# IMC300A register map
Vendor: Infineon; File version: 1.0.0
CPU: CM0 r0p0, little endian, no MPU, no FPU, 2 interrupt priority bits
Registers are 32-bit, read-write, reset 0x0 unless marked. A register's access mark holds for its fields unless they carry their own. Offsets are from the block's base; [hi:lo] are bit positions; {n}, {i} and the like mark numbered series; 'fields as' and 'values as' point back to an identical list.

## PORT1
Base 0x40040100
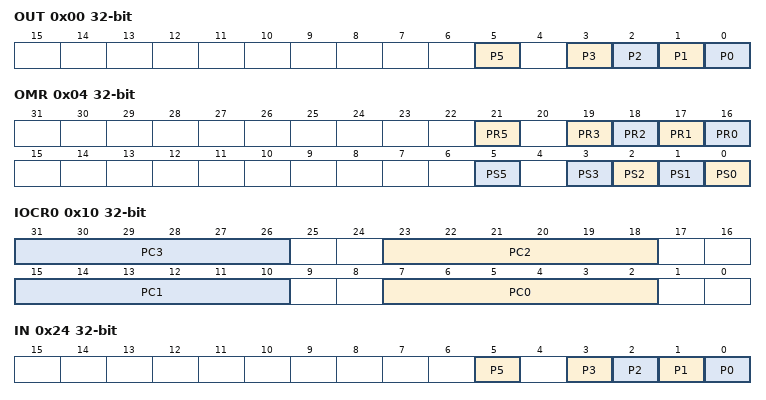
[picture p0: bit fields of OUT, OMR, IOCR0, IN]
0x00 OUT — Port 1 Output Register
  [all] fields
    0=The output level of P1.x is 0; 1=The output level of P1.x is 1
  [5] P5 — Port 1 Output Bit 5
  [n] P{n} (n=0..3) — Port 1 Output Bit {n}
0x04 OMR wo — Port 1 Output Modification Register
  [21] PR5 — Port 1 Reset Bit 5
  [n+16] PR{n} (n=0..3) — Port 1 Reset Bit {n}
  [5] PS5 — Port 1 Set Bit 5
  [n] PS{n} (n=0..3) — Port 1 Set Bit {n}
0x10 IOCR0 — Port 1 Input/Output Control Register 0
  [all] fields
    0=Input - No internal pull device active; 1=Input - Internal pull-down device active; 2=Input - Internal pull-up device active; 3=Input - No internal pull device, Pn_OUTx = input value; 4=Input inverted - No internal pull device active; 5=Input inverted - Internal pull-down device active; 6=Input inverted - Internal pull-up device active; 7=Input inverted - No internal pull device, Pn_OUTx = input value; 32=Output Push-Pull - General-purpose output; {v}=Output Push-Pull - Alternate output function {v-32} (v=33..41); 48=Output Open Drain - General-purpose output; {v}=Output Open Drain - Alternate output function {v-48} (v=49..57)
  [8n+7:8n+2] PC{n} (n=0..3) — Port Control for Port 1 Pin {n}
0x14 IOCR4 — Port 1 Input/Output Control Register 4
  [15:10] PC5 — Port Control for Port 1 Pin 5
    values as the fields of IOCR0
0x24 IN ro (reset mask 0xFFFFF000) — Port 1 Input Register
  [all] fields
    0=The input level of P1.x is 0; 1=The input level of P1.x is 1
  [5] P5 — Port 1 Input Bit 5
  [n] P{n} (n=0..3) — Port 1 Input Bit {n}
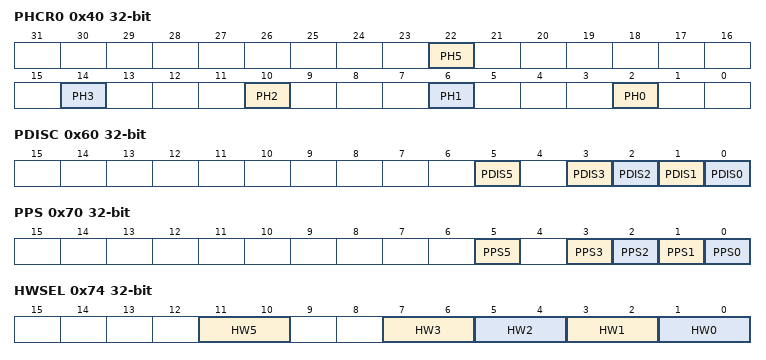
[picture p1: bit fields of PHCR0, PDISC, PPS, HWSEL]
0x40 PHCR0 — Port 1 Pad Hysteresis Control Register 0
  [22] PH5 — Pad Hysteresis for P1.5
  [14] PH3 — Pad Hysteresis for P1.3
  [10] PH2 — Pad Hysteresis for P1.2
  [6] PH1 — Pad Hysteresis for P1.1
  [2] PH0 — Pad Hysteresis for P1.0
0x60 PDISC ro (reset mask 0xFFFFF000) — Port 1 Pin Function Decision Control Register
  [all] fields
    0=Pad P1.x is enabled; 1=Pad P1.x is disabled
  [5] PDIS5 — Pad Disable for Port 1 Pin 5
  [n] PDIS{n} (n=0..3) — Pad Disable for Port 1 Pin {n}
0x70 PPS — Port 1 Pin Power Save Register
  [all] fields
    0=Pin Power Save of P1.x is disabled; 1=Pin Power Save of P1.x is enabled
  [5] PPS5 — Port 1 Pin Power Save Bit 5
  [n] PPS{n} (n=0..3) — Port 1 Pin Power Save Bit {n}
0x74 HWSEL — Port 1 Pin Hardware Select Register
  [all] fields
    0=Software control only; 1=HW0 control path can override the software configuration; 2=HW1 control path can override the software configuration
  [11:10] HW5 — Port 1 Pin Hardware Select Bit 5
  [2n+1:2n] HW{n} (n=0..3) — Port 1 Pin Hardware Select Bit {n}

## PORT4
Base 0x40040400
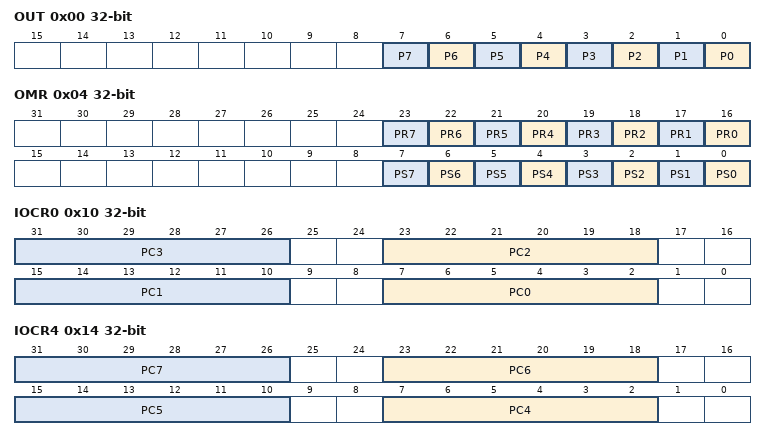
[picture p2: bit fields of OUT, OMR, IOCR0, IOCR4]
0x00 OUT — Port 4 Output Register
  [all] fields
    0=The output level of P4.x is 0; 1=The output level of P4.x is 1
  [n] P{n} (n=0..7) — Port 4 Output Bit {n}
0x04 OMR wo — Port 4 Output Modification Register
  [n+16] PR{n} (n=0..7) — Port 4 Reset Bit {n}
  [n] PS{n} (n=0..7) — Port 4 Set Bit {n}
0x10 IOCR0 — Port 4 Input/Output Control Register 0
  [all] fields
    0=Input - No internal pull device active; 1=Input - Internal pull-down device active; 2=Input - Internal pull-up device active; 3=Input - No internal pull device, Pn_OUTx = input value; 4=Input inverted - No internal pull device active; 5=Input inverted - Internal pull-down device active; 6=Input inverted - Internal pull-up device active; 7=Input inverted - No internal pull device, Pn_OUTx = input value; 32=Output Push-Pull - General-purpose output; {v}=Output Push-Pull - Alternate output function {v-32} (v=33..41); 48=Output Open Drain - General-purpose output; {v}=Output Open Drain - Alternate output function {v-48} (v=49..57)
  [8n+7:8n+2] PC{n} (n=0..3) — Port Control for Port 4 Pin {n}
0x14 IOCR4 — Port 4 Input/Output Control Register 4
  [all] fields
    values as the fields of IOCR0
  [8n-25:8n-30] PC{n} (n=4..7) — Port Control for Port 4 Pin {n}
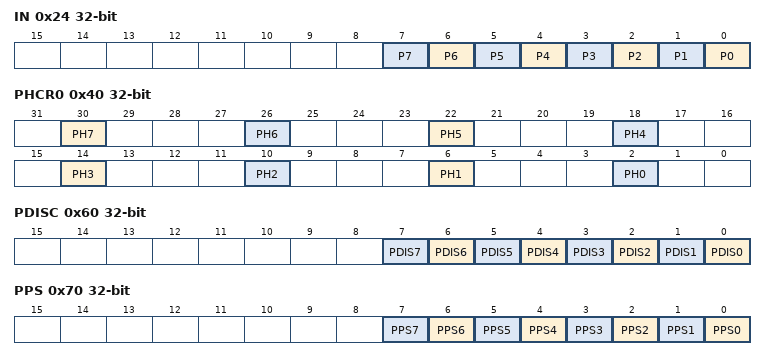
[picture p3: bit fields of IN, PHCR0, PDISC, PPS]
0x24 IN ro (reset mask 0xFFFFF000) — Port 4 Input Register
  [all] fields
    0=The input level of P4.x is 0; 1=The input level of P4.x is 1
  [n] P{n} (n=0..7) — Port 4 Input Bit {n}
0x40 PHCR0 — Port 4 Pad Hysteresis Control Register 0
  [30] PH7 — Pad Hysteresis for P4.7
  [26] PH6 — Pad Hysteresis for P4.6
  [22] PH5 — Pad Hysteresis for P4.5
  [18] PH4 — Pad Hysteresis for P4.4
  [14] PH3 — Pad Hysteresis for P4.3
  [10] PH2 — Pad Hysteresis for P4.2
  [6] PH1 — Pad Hysteresis for P4.1
  [2] PH0 — Pad Hysteresis for P4.0
0x60 PDISC ro (reset mask 0xFFFFF000) — Port 4 Pin Function Decision Control Register
  [all] fields
    0=Pad P4.x is enabled; 1=Pad P4.x is disabled
  [n] PDIS{n} (n=0..7) — Pad Disable for Port 4 Pin {n}
0x70 PPS — Port 4 Pin Power Save Register
  [all] fields
    0=Pin Power Save of P4.x is disabled; 1=Pin Power Save of P4.x is enabled
  [n] PPS{n} (n=0..7) — Port 4 Pin Power Save Bit {n}
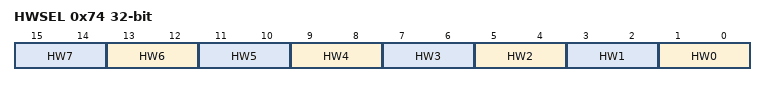
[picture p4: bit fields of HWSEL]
0x74 HWSEL — Port 4 Pin Hardware Select Register
  [all] fields
    0=Software control only; 1=HW0 control path can override the software configuration; 2=HW1 control path can override the software configuration
  [2n+1:2n] HW{n} (n=0..7) — Port 4 Pin Hardware Select Bit {n}
